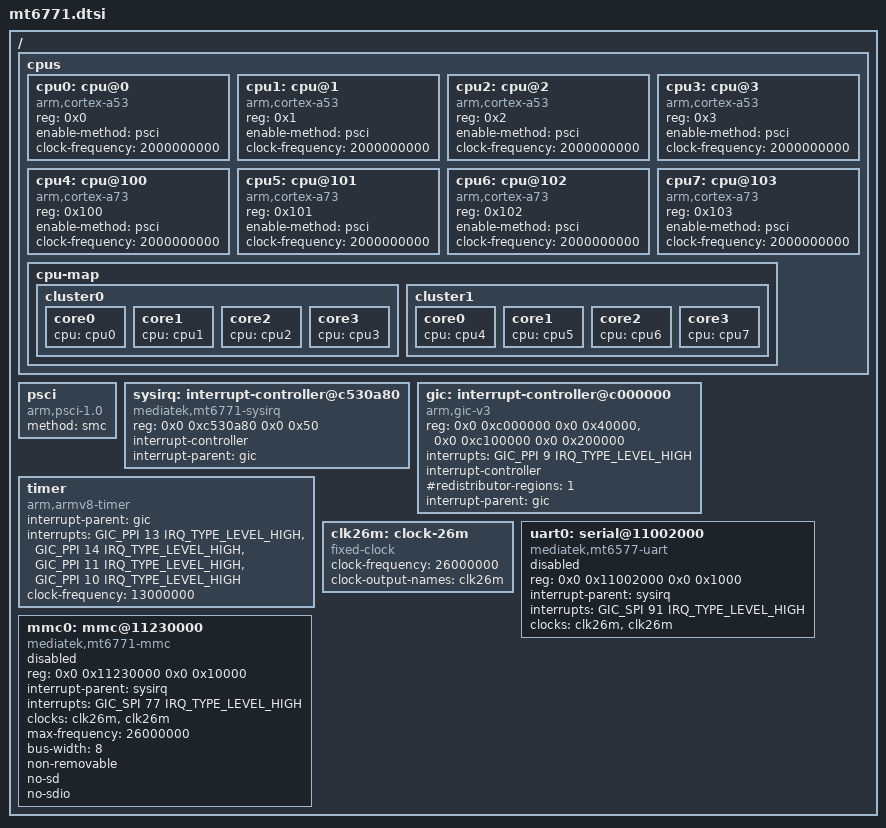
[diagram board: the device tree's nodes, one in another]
// SPDX-License-Identifier: GPL-2.0+
/*
 * Minimal MediaTek MT6771 (Helio P60) SoC skeleton.
 */

#include <dt-bindings/interrupt-controller/arm-gic.h>
#include <dt-bindings/interrupt-controller/irq.h>

/ {
	#address-cells = <2>;
	#size-cells = <2>;

	cpus {
		#address-cells = <1>;
		#size-cells = <0>;
		cpu0: cpu@0 { device_type = "cpu"; compatible = "arm,cortex-a53"; reg = <0x0>; enable-method = "psci"; clock-frequency = <2000000000>; };
		cpu1: cpu@1 { device_type = "cpu"; compatible = "arm,cortex-a53"; reg = <0x1>; enable-method = "psci"; clock-frequency = <2000000000>; };
		cpu2: cpu@2 { device_type = "cpu"; compatible = "arm,cortex-a53"; reg = <0x2>; enable-method = "psci"; clock-frequency = <2000000000>; };
		cpu3: cpu@3 { device_type = "cpu"; compatible = "arm,cortex-a53"; reg = <0x3>; enable-method = "psci"; clock-frequency = <2000000000>; };
		cpu4: cpu@100 { device_type = "cpu"; compatible = "arm,cortex-a73"; reg = <0x100>; enable-method = "psci"; clock-frequency = <2000000000>; };
		cpu5: cpu@101 { device_type = "cpu"; compatible = "arm,cortex-a73"; reg = <0x101>; enable-method = "psci"; clock-frequency = <2000000000>; };
		cpu6: cpu@102 { device_type = "cpu"; compatible = "arm,cortex-a73"; reg = <0x102>; enable-method = "psci"; clock-frequency = <2000000000>; };
		cpu7: cpu@103 { device_type = "cpu"; compatible = "arm,cortex-a73"; reg = <0x103>; enable-method = "psci"; clock-frequency = <2000000000>; };

		cpu-map {
			cluster0 { core0 { cpu = <&cpu0>; }; core1 { cpu = <&cpu1>; }; core2 { cpu = <&cpu2>; }; core3 { cpu = <&cpu3>; }; };
			cluster1 { core0 { cpu = <&cpu4>; }; core1 { cpu = <&cpu5>; }; core2 { cpu = <&cpu6>; }; core3 { cpu = <&cpu7>; }; };
		};
	};

	psci {
		compatible = "arm,psci-1.0";
		method = "smc";
	};

	sysirq: interrupt-controller@c530a80 {
		compatible = "mediatek,mt6771-sysirq", "mediatek,mt6577-sysirq";
		reg = <0x0 0xc530a80 0x0 0x50>;
		interrupt-controller;
		#address-cells = <0>;
		#interrupt-cells = <3>;
		interrupt-parent = <&gic>;
	};

	gic: interrupt-controller@c000000 {
		compatible = "arm,gic-v3";
		reg = <0x0 0xc000000 0x0 0x40000>,
		      <0x0 0xc100000 0x0 0x200000>;
		interrupts = <GIC_PPI 9 IRQ_TYPE_LEVEL_HIGH>;
		interrupt-controller;
		#address-cells = <0>;
		#interrupt-cells = <3>;
		#redistributor-regions = <1>;
		interrupt-parent = <&gic>;
	};

	timer {
		compatible = "arm,armv8-timer";
		interrupt-parent = <&gic>;
		interrupts = <GIC_PPI 13 IRQ_TYPE_LEVEL_HIGH>, <GIC_PPI 14 IRQ_TYPE_LEVEL_HIGH>, <GIC_PPI 11 IRQ_TYPE_LEVEL_HIGH>, <GIC_PPI 10 IRQ_TYPE_LEVEL_HIGH>;
		clock-frequency = <13000000>;
	};

	clk26m: clock-26m {
		compatible = "fixed-clock";
		#clock-cells = <0>;
		clock-frequency = <26000000>;
		clock-output-names = "clk26m";
	};

	uart0: serial@11002000 {
		compatible = "mediatek,mt6577-uart";
		reg = <0x0 0x11002000 0x0 0x1000>;
		interrupt-parent = <&sysirq>;
		interrupts = <GIC_SPI 91 IRQ_TYPE_LEVEL_HIGH>;
		clocks = <&clk26m>, <&clk26m>;
		clock-names = "baud", "bus";
		status = "disabled"; // 让板级 DTS 去开启它
	};

	mmc0: mmc@11230000 {
		compatible = "mediatek,mt6771-mmc", "mediatek,mt2712-mmc";
		reg = <0x0 0x11230000 0x0 0x10000>;
		interrupt-parent = <&sysirq>;
		interrupts = <GIC_SPI 77 IRQ_TYPE_LEVEL_HIGH>;
		clocks = <&clk26m>, <&clk26m>;
		clock-names = "source", "hclk";
		max-frequency = <26000000>;
		bus-width = <8>;
		non-removable;
		no-sd;
		no-sdio;
		status = "disabled"; // 让板级 DTS 去开启它
	};
};
